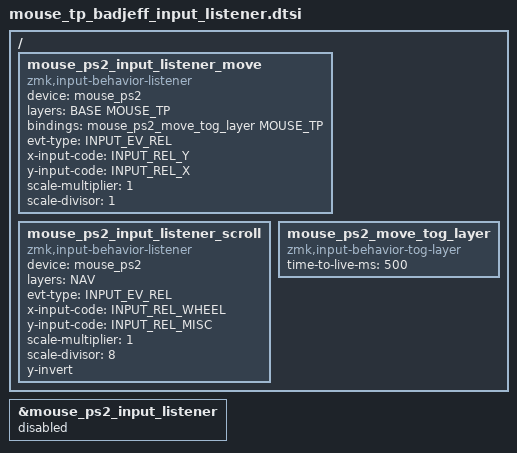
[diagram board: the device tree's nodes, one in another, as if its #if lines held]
// Important:
// Make sure this file is included AFTER `mouse_tp.dtsi`.

#ifdef HAS_MOUSE_TP_BADJEFF_INPUT_LISTENER
  #ifdef HAS_MOUSE_TP
    #ifdef MOUSE_PS2_DT_PRESENT
    // Disable original input listener
      &mouse_ps2_input_listener {
        status = "disabled";
      };
      
      / {
        // Badjeff's input listener for mouse movement
        mouse_ps2_input_listener_move {
          compatible = "zmk,input-behavior-listener";
          device = <&mouse_ps2>;
  
          // The TP will move the mouse on all layers except for
          // SYM and NAV
          layers = <
            BASE
            MOUSE_TP
          >;
  
          // Auto toggle Mouse_TP layer when the mouse moves
          bindings = <&mouse_ps2_move_tog_layer MOUSE_TP>;
  
          // Use mouse movement event codes
          evt-type = <INPUT_EV_REL>;
          x-input-code = <INPUT_REL_Y>;
          y-input-code = <INPUT_REL_X>;
  
          scale-multiplier = <1>;
          scale-divisor = <1>;
        };
  
        // Input listener for scrolling
        mouse_ps2_input_listener_scroll {
          compatible = "zmk,input-behavior-listener";
          device = <&mouse_ps2>;
  
          layers = <
            NAV
          >;
  
          // Use scroll event codes
          evt-type = <INPUT_EV_REL>;
          x-input-code = <INPUT_REL_WHEEL>;
          y-input-code = <INPUT_REL_MISC>;
  
          // Slow down the scrolling
          scale-multiplier = <1>;
          scale-divisor = <8>;

          y-invert;
        };
  
        mouse_ps2_move_tog_layer: mouse_ps2_move_tog_layer {
                compatible = "zmk,input-behavior-tog-layer";
                #binding-cells = <1>;
                time-to-live-ms = <500>;
        };
      };
    #endif  // MOUSE_PS2_DT_PRESENT
  #endif  // HAS_MOUSE_TP
#endif  // HAS_MOUSE_TP_BADJEFF_INPUT_LISTENER
